CM_ "IMPORT vw_meb_common.dbc";

BO_ 258 ESC_50: 48 XXX
 SG_ CHECKSUM : 0|8@1+ (1,0) [0|255] "" XXX
 SG_ COUNTER : 8|4@1+ (1,0) [0|15] "" XXX
 SG_ Lateral_Accel : 16|8@1+ (0.15,-18.9) [0|255] "Unit_MeterPerSquareSecond" XXX
 SG_ Longitudinal_Accel : 24|10@1+ (0.03125,-16) [0|255] "Unit_MeterPerSquareSecond" XXX
 SG_ Yaw_Rate : 40|14@1+ (0.01,0) [0|16383] "Unit_DegreePerSecond" XXX
 SG_ Yaw_Rate_Sign : 54|1@0+ (1,0) [0|1] "" XXX
 SG_ Brake_Power : 80|8@1+ (1,-100) [0|255] "" XXX
 SG_ Brake_01 : 90|1@0+ (1,0) [0|1] "" XXX
 SG_ Regen_Braking : 123|1@1+ (1,0) [0|7] "" XXX
 SG_ Brake_02 : 125|1@0+ (1,0) [0|1] "" XXX
 SG_ Standstill : 171|1@0+ (1,0) [0|1] "" XXX
 SG_ NEW_SIGNAL_3 : 180|1@0+ (1,0) [0|1] "" XXX
 SG_ Longitudinal_Speed : 181|10@1+ (0.25,0) [0|255] "Unit_KilometerPerHour" XXX
 SG_ Brake_Power_02 : 226|8@1+ (1,-100) [0|63] "" XXX
 SG_ NEW_SIGNAL_2 : 236|9@1+ (1,0) [0|7] "" XXX
 SG_ NEW_SIGNAL_1 : 248|4@1+ (1,0) [0|15] "" XXX

BO_ 252 ESC_51: 48 XXX
 SG_ CHECKSUM : 0|8@1+ (1,0) [0|255] "" XXX
 SG_ COUNTER : 8|4@1+ (1,0) [0|15] "" XXX
 SG_ NEW_SIGNAL_2 : 14|6@1+ (1,0) [0|3] "" XXX
 SG_ AEB_Breaking_01 : 24|8@1+ (1,0) [0|255] "" XXX
 SG_ AEB_Breaking_02 : 32|8@1+ (1,0) [0|255] "" XXX
 SG_ Accelerator_Higher_Speed : 40|1@0+ (1,0) [0|1] "" XXX
 SG_ Brake_Pressure : 42|9@1+ (0.195,0) [0|100] "Unit_Percent" XXX
 SG_ NEW_SIGNAL_1 : 52|8@1+ (1,0) [0|15] "" XXX
 SG_ HL_Radgeschw : 64|16@1+ (0.0075,0) [0|491.5125] "Unit_KilometerPerHour" XXX
 SG_ HR_Radgeschw : 80|16@1+ (0.0075,0) [0|491.5125] "Unit_KilometerPerHour" XXX
 SG_ VL_Radgeschw : 96|16@1+ (0.0075,0) [0|491.5125] "Unit_KilometerPerHour" XXX
 SG_ VR_Radgeschw : 112|16@1+ (0.0075,0) [0|491.5125] "Unit_KilometerPerHour" XXX
 SG_ NEW_SIGNAL_3 : 128|4@1+ (1,0) [0|15] "" XXX
 SG_ HL_Brake_Pressure : 152|8@1+ (1,0) [0|100] "" XXX
 SG_ HR_Brake_Pressure : 160|8@1+ (1,0) [0|100] "" XXX
 SG_ VL_Brake_Pressure : 168|8@1+ (1,0) [0|100] "" XXX
 SG_ VR_Brake_Pressure : 176|8@1+ (1,0) [0|100] "" XXX
 SG_ Steering_Wheel_CW : 184|8@1+ (1.67,0) [0|255] "" XXX
 SG_ Steering_Wheel_CCW : 192|8@1+ (1.67,0) [0|255] "" XXX
 SG_ ESC_v_Signal : 328|13@1+ (0.052,-107.016) [0|63] "" XXX
 SG_ NEW_SIGNAL_4 : 342|13@1+ (1,0) [0|3] "" XXX

BO_ 219 AWV_03: 48 XXX
 SG_ CHECKSUM : 0|8@1+ (1,0) [0|255] "" XXX
 SG_ COUNTER : 8|4@1+ (1,0) [0|15] "" XXX
 SG_ Pre_FCW : 64|1@0+ (1,0) [0|1] "" XXX
 SG_ FCW_Active : 76|1@0+ (1,0) [0|1] "" XXX

BO_ 267 Motor_51: 32 XXX
 SG_ CHECKSUM : 0|8@1+ (1,0) [0|255] "" XXX
 SG_ COUNTER : 8|4@1+ (1,0) [0|15] "" XXX
 SG_ Accel_Pedal_Pressure : 12|9@1+ (0.4,0) [0|255] "" XXX
 SG_ Accel_Low_Pressed_Support : 21|1@1+ (1,0) [0|7] "" XXX
 SG_ TSK_Status : 88|3@1+ (1,0) [0|7] "" XXX
 SG_ TSK_Limiter_ausgewaehlt : 95|1@1+ (1,0) [0|3] "" XXX

BO_ 317 QFK_01: 32 XXX
 SG_ CHECKSUM : 0|8@1+ (1,0) [0|255] "" XXX
 SG_ COUNTER : 8|4@1+ (1,0) [0|15] "" XXX
 SG_ NEW_SIGNAL_5 : 12|1@0+ (1,0) [0|1] "" XXX
 SG_ HCA_No_Override : 14|1@0+ (1,0) [0|1] "" XXX
 SG_ NEW_SIGNAL_8 : 16|1@0+ (1,0) [0|1] "" XXX
 SG_ LatCon_HCA_Accept : 17|2@1+ (1,0) [0|3] "" XXX
 SG_ NEW_SIGNAL_2 : 19|1@0+ (1,0) [0|1] "" XXX
 SG_ LatCon_HCA_Status : 20|3@1+ (1,0) [0|15] "" XXX
 SG_ NEW_SIGNAL_1 : 23|1@0+ (1,0) [0|1] "" XXX
 SG_ NEW_SIGNAL_10 : 24|1@0+ (1,0) [0|1] "" XXX
 SG_ NEW_SIGNAL_6 : 30|3@0+ (1,0) [0|1] "" XXX
 SG_ NEW_SIGNAL_7 : 34|3@0+ (1,0) [0|1] "" XXX
 SG_ Steering_Angle_VZ : 36|1@0+ (1,0) [0|1] "" XXX
 SG_ Curvature : 40|15@1+ (6.7e-06,0) [0|65535] "" XXX
 SG_ Curvature_VZ : 55|1@0+ (1,0) [0|1] "" XXX
 SG_ NEW_SIGNAL_3 : 56|7@1+ (1,0) [0|63] "" XXX
 SG_ NEW_SIGNAL_4 : 63|1@0+ (1,0) [0|1] "" XXX
 SG_ Steering_Angle : 76|17@1+ (0.00906,0) [0|32767] "" XXX

BO_ 389241616 MEB_Camera_09: 8 XXX

BO_ 313 VMM_02: 32 XXX
 SG_ CHECKSUM : 0|8@1+ (1,0) [0|255] "" XXX
 SG_ COUNTER : 8|4@1+ (1,0) [0|15] "" XXX
 SG_ FCW_Reaction_1 : 12|1@0+ (1,0) [0|1] "" XXX
 SG_ Brake_Pressed_1 : 16|1@0+ (1,0) [0|1] "" XXX
 SG_ Brake_Pressed_2 : 27|1@0+ (1,0) [0|1] "" XXX
 SG_ AEB_Active : 31|1@0+ (1,0) [0|1] "" XXX
 SG_ ESP_Hold : 35|1@0+ (1,0) [0|1] "" XXX
 SG_ Brake_Pressed_3 : 48|1@0+ (1,0) [0|1] "" XXX
 SG_ FCW_Reaction_2 : 56|1@1+ (1,0) [0|1] "" XXX
 SG_ Brake_Pressure : 76|11@1+ (1,0) [0|100] "" XXX
 SG_ FCW_Reaction_3 : 88|5@1+ (1,0) [0|31] "" XXX

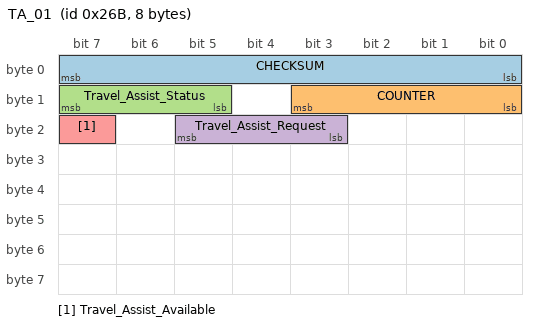
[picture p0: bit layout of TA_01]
BO_ 619 TA_01: 8 XXX
 SG_ CHECKSUM : 0|8@1+ (1,0) [0|255] "" XXX
 SG_ COUNTER : 8|4@1+ (1,0) [0|15] "" XXX
 SG_ Travel_Assist_Status : 13|3@1+ (1,0) [0|3] "" XXX
 SG_ Travel_Assist_Request : 19|3@1+ (1,0) [0|7] "" XXX
 SG_ Travel_Assist_Available : 23|1@1+ (1,0) [0|1] "" XXX

VAL_ 267 TSK_Status 0 "init" 1 "disabled" 2 "enabled" 3 "regulating" 4 "accel_pedal_override" 5 "brake_only" 6 "temp_fault" 7 "perm_fault";
VAL_ 317 LatCon_HCA_Status 0 "disabled" 1 "initializing" 2 "ready" 3 "fault" 4 "active" 5 "preempted" 6 "fault" 7 "rejected";
VAL_ 619 Travel_Assist_Status 4 "enabled" 0 "disabled" 2 "ready" 3 "pre_ready";
VAL_ 619 Travel_Assist_Request 4 "enable" 3 "disable" 0 "no_request" 1 "error";
VAL_ 619 Travel_Assist_Available 0 "not_available" 1 "available";
